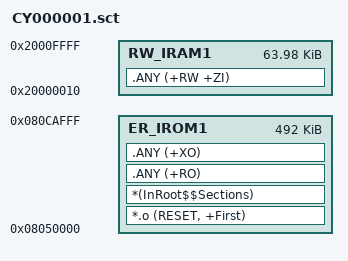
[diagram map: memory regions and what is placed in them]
; *************************************************************
; *** Scatter-Loading Description File generated by uVision ***
; *************************************************************

LR_IROM1 0x08005000 0x0007B000  {    ; load region size_region
  ER_IROM1 0x08050000 0x0007B000  {  ; load address = execution address
   *.o (RESET, +First)
   *(InRoot$$Sections)
   .ANY (+RO)
   .ANY (+XO)
  }
  RW_IRAM1 0x20000010 0x0000FFF0  {  ; RW data
   .ANY (+RW +ZI)
  }
}

